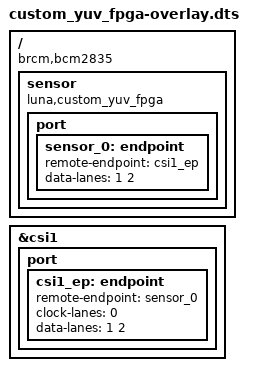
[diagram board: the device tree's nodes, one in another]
// SPDX-License-Identifier: GPL-2.0-only
// Definitions for Dummy CSI2 sensor
/dts-v1/;
/plugin/;

/{
	compatible = "brcm,bcm2835";

	fragment@0 {
		target-path = "/";
		__overlay__ {
			sensor: sensor {
				compatible = "luna,custom_yuv_fpga";
				status = "okay";

				port {
					sensor_0: endpoint {
						remote-endpoint = <&csi1_ep>;
					};
				};
			};
		};
	};

	fragment@1 {
		target = <&csi1>;
		__overlay__ {
			status = "okay";

			port {
				csi1_ep: endpoint {
					remote-endpoint = <&sensor_0>;
					clock-lanes = <0>;
					data-lanes = <1 2>;
				};
			};
		};
	};


	fragment@6 {
		target = <&sensor_0>;
		__overlay__ {
			data-lanes = <1 2>;
		};
	};


	__overrides__ {
		2lanes = <0>, "-2+3-6+7";
		4lanes = <0>, "-2+4-6+8";
		noncontinuous = <0>, "+5+9";
	};
};
